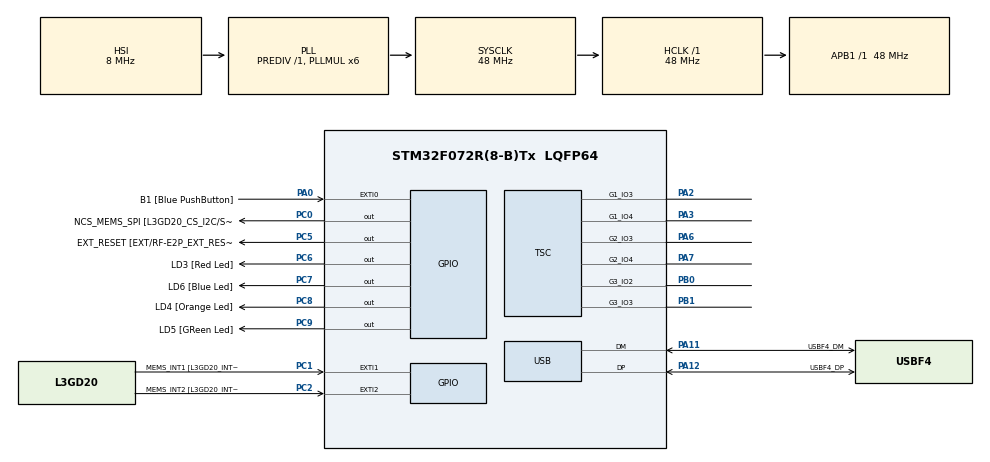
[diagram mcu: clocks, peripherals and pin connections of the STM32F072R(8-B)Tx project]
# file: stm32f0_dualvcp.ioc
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Mcu.Family=STM32F0
Mcu.Name=STM32F072R(8-B)Tx
Mcu.Package=LQFP64
NVIC.USB_IRQn=true\:0\:0\:false\:false\:true\:false\:true\:true
PA0.GPIO_Label=B1 [Blue PushButton]
PA0.GPIO_ModeDefaultEXTI=GPIO_MODE_EVT_RISING
PA0.Signal=GPXTI0
PA11.GPIO_Label=USBF4_DM
PA11.Mode=Device
PA11.Signal=USB_DM
PA12.GPIO_Label=USBF4_DP
PA12.Mode=Device
PA12.Signal=USB_DP
PA13.GPIO_Label=SWDIO
PA13.Mode=Serial_Wire
PA13.Signal=SYS_SWDIO
PA14.GPIO_Label=SWCLK
PA14.Mode=Serial_Wire
PA14.Signal=SYS_SWCLK
PA2.Mode=G1_IO3-Channel
PA2.Signal=TSC_G1_IO3
PA3.Mode=G1_IO4-Sampling
PA3.Signal=TSC_G1_IO4
PA6.Mode=G2_IO3-Channel
PA6.Signal=TSC_G2_IO3
PA7.Mode=G2_IO4-Sampling
PA7.Signal=TSC_G2_IO4
PB0.Mode=G3_IO2-Channel
PB0.Signal=TSC_G3_IO2
PB1.Mode=G3_IO3-Sampling
PB1.Signal=TSC_G3_IO3
PB10.GPIO_Label=I2C2_SCL[EXT/RF-E2P_SCL]
PB10.GPIO_Pu=GPIO_PULLUP
PB10.Signal=I2C2_SCL
PB11.GPIO_Label=I2C2_SDA[EXT/RF-E2P_SDA]
PB11.GPIO_Pu=GPIO_PULLUP
PB11.Signal=I2C2_SDA
PB13.GPIO_Label=SPI2_SCK [L3GD20_SCL/SPC]
PB13.Signal=SPI2_SCK
PB14.GPIO_Label=SPI2_MISO [L3GD20_SDO]
PB14.Signal=SPI2_MISO
PB15.GPIO_Label=SPI2_MOSI [L3GD20_SDA/SDI]
PB15.Signal=SPI2_MOSI
PC0.GPIO_Label=NCS_MEMS_SPI [L3GD20_CS_I2C/SPI]
PC0.Signal=GPIO_Output
PC1.GPIO_Label=MEMS_INT1 [L3GD20_INT1]
PC1.GPIO_ModeDefaultEXTI=GPIO_MODE_EVT_RISING
PC1.Signal=GPXTI1
PC2.GPIO_Label=MEMS_INT2 [L3GD20_INT2]
PC2.GPIO_ModeDefaultEXTI=GPIO_MODE_EVT_RISING
PC2.Signal=GPXTI2
PC5.GPIO_Label=EXT_RESET [EXT/RF-E2P_EXT_RESET]
PC5.Signal=GPIO_Output
PC6.GPIO_Label=LD3 [Red Led]
PC6.Signal=GPIO_Output
PC7.GPIO_Label=LD6 [Blue Led]
PC7.Signal=GPIO_Output
PC8.GPIO_Label=LD4 [Orange Led]
PC8.Signal=GPIO_Output
PC9.GPIO_Label=LD5 [GReen Led]
PC9.Signal=GPIO_Output
ProjectManager.HeapSize=0x200
ProjectManager.StackSize=0x400
ProjectManager.TargetToolchain=STM32CubeIDE
RCC.AHBFreq_Value=48000000
RCC.APB1Freq_Value=48000000
RCC.APB1TimFreq_Value=48000000
RCC.HCLKFreq_Value=48000000
RCC.PLLMUL=RCC_PLL_MUL6
RCC.SYSCLKFreq_VALUE=48000000
RCC.SYSCLKSource=RCC_SYSCLKSOURCE_PLLCLK
USB.phy_itface=PCD_PHY_EMBEDDED
USB.speed=PCD_SPEED_FULL
USB_DEVICE.CLASS_NAME_FS=CDC
USB_DEVICE.VirtualMode=Cdc
USB_DEVICE.VirtualModeFS=Cdc_FS
VP_USB_DEVICE_VS_USB_DEVICE_CDC_FS.Mode=CDC_FS
board=STM32F072B-DISCO

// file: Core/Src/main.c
/* USER CODE BEGIN Header */
/**
  ******************************************************************************
  * @file           : main.c  dual_vcp USB
  * @brief          : Main program body
  ******************************************************************************
  * @attention
  *
  * Copyright (c) 2024 STMicroelectronics.
  * All rights reserved.
  *
  * This software is licensed under terms that can be found in the LICENSE file
  * in the root directory of this software component.
  * If no LICENSE file comes with this software, it is provided AS-IS.
  *
  ******************************************************************************

F072B DISCO bd -- DO NOT RUN MX code gen as it will overwrite USB code.
example composite CDC, 2 USB serial ports!

======== size of this build ===
  text	   data	    bss	    dec	    hex	filename
  32992	    608	   4400	  38000	   9470	stm32f0_dualvcp.elf

 LED GPIOs
 LD3: 	red
 4:		orange
 5:		green
 6		blue

  */
/* USER CODE END Header */
#include "main.h"
#include "tsc.h"
#include "usb_device.h"
#include "usbd_cdc_if.h"
#include "usbd_cdc.h"
#include "gpio.h"

void SystemClock_Config(void);

/* USER CODE BEGIN 0 */
uint32_t debug_cdc_bytes_rx;

//testing 2 endpoints, outputs to other endpoint, limited to 64 bytes.
// otherwise use polling in main() to wait for TX empty.
void USB_CDC_RxHandler(uint8_t *Buf, uint32_t Len, uint16_t ep_out) {

	debug_cdc_bytes_rx += Len;

	if(ep_out == CDC_OUT_EP1){
		HAL_GPIO_TogglePin(LD6_GPIO_Port, LD6_Pin); //blue COM10
	}
	else{
		HAL_GPIO_TogglePin(LD4_GPIO_Port, LD4_Pin); //ora  COM11
	}

	//convert to EP_IN_xx for "other" ep
	uint16_t ep_in = (ep_out == CDC_OUT_EP1) ? CDC_IN_EP2 : CDC_IN_EP1;

	if( USBD_OK != CDC_Transmit_FS( Buf, Len, ep_in ) ){
		HAL_GPIO_WritePin(LD3_GPIO_Port, LD3_Pin, GPIO_PIN_SET);  //red if busy
	}else{
		HAL_GPIO_WritePin(LD3_GPIO_Port, LD3_Pin, GPIO_PIN_RESET);
	}

}
/* USER CODE END 0 */

int main(void)
{

  /* MCU Configuration--------------------------------------------------------*/

  /* Reset of all peripherals, Initializes the Flash interface and the Systick. */
  HAL_Init();

  /* Configure the system clock */
  SystemClock_Config();

  /* Initialize all configured peripherals */
  MX_GPIO_Init();
  //MX_TSC_Init();
  MX_USB_DEVICE_Init();

  /* Infinite loop */
  while (1)
  {

    /* USER CODE BEGIN 3 */
	 if( (HAL_GetTick() % 1000) == 0 ){
		 HAL_GPIO_TogglePin(LD5_GPIO_Port, LD5_Pin);	//funky blinky
	 }
  }
  /* USER CODE END 3 */
}

void SystemClock_Config(void)
{
  RCC_OscInitTypeDef RCC_OscInitStruct = {0};
  RCC_ClkInitTypeDef RCC_ClkInitStruct = {0};
  RCC_PeriphCLKInitTypeDef PeriphClkInit = {0};

  /** Initializes the RCC Oscillators according to the specified parameters
  * in the RCC_OscInitTypeDef structure.
  */
  RCC_OscInitStruct.OscillatorType = RCC_OSCILLATORTYPE_HSI|RCC_OSCILLATORTYPE_HSI48;
  RCC_OscInitStruct.HSIState = RCC_HSI_ON;
  RCC_OscInitStruct.HSI48State = RCC_HSI48_ON;
  RCC_OscInitStruct.HSICalibrationValue = RCC_HSICALIBRATION_DEFAULT;
  RCC_OscInitStruct.PLL.PLLState = RCC_PLL_ON;
  RCC_OscInitStruct.PLL.PLLSource = RCC_PLLSOURCE_HSI;
  RCC_OscInitStruct.PLL.PLLMUL = RCC_PLL_MUL6;
  RCC_OscInitStruct.PLL.PREDIV = RCC_PREDIV_DIV1;
  if (HAL_RCC_OscConfig(&RCC_OscInitStruct) != HAL_OK)
  {
    Error_Handler();
  }

  /** Initializes the CPU, AHB and APB buses clocks
  */
  RCC_ClkInitStruct.ClockType = RCC_CLOCKTYPE_HCLK|RCC_CLOCKTYPE_SYSCLK
                              |RCC_CLOCKTYPE_PCLK1;
  RCC_ClkInitStruct.SYSCLKSource = RCC_SYSCLKSOURCE_PLLCLK;
  RCC_ClkInitStruct.AHBCLKDivider = RCC_SYSCLK_DIV1;
  RCC_ClkInitStruct.APB1CLKDivider = RCC_HCLK_DIV1;

  if (HAL_RCC_ClockConfig(&RCC_ClkInitStruct, FLASH_LATENCY_1) != HAL_OK)
  {
    Error_Handler();
  }
  PeriphClkInit.PeriphClockSelection = RCC_PERIPHCLK_USB;
  PeriphClkInit.UsbClockSelection = RCC_USBCLKSOURCE_HSI48;

  if (HAL_RCCEx_PeriphCLKConfig(&PeriphClkInit) != HAL_OK)
  {
    Error_Handler();
  }
}

void Error_Handler(void)
{
  __disable_irq();
  while (1)
  {
  }
}
